# oca_i3c_wrap: IP-XACT component
VLNV tenstorrent.com:ocah:oca_i3c_wrap:1.0

## Address spaces and blocks
oca_i3c_wrap_mmap.oca_i3c_wrap: base 'h0, range 'h6000, width 32

## Registers
Registers are 32-bit, read-write, reset 0x0 unless marked. A register's access mark holds for its fields unless they carry their own. Offsets are from the block's base; lines under a group give offsets from that group; [hi:lo] are bit positions; {n}, {i} and the like mark numbered series; 'fields as' and 'values as' point back to an identical list; <NAME> marks a mode.

## oca_i3c_wrap_mmap.oca_i3c_wrap — Wrapper address map instantiating the per-controller I3C CSR blocks.
Base 0x00000000
{0x0+0x1000*i} i3c_csr[{i}] (i=0..5) group
  0x00 I3CBase group
    0x00 HCI_VERSION ro reset 0x120 — Identifies the implemented MIPI I3C HCI version.
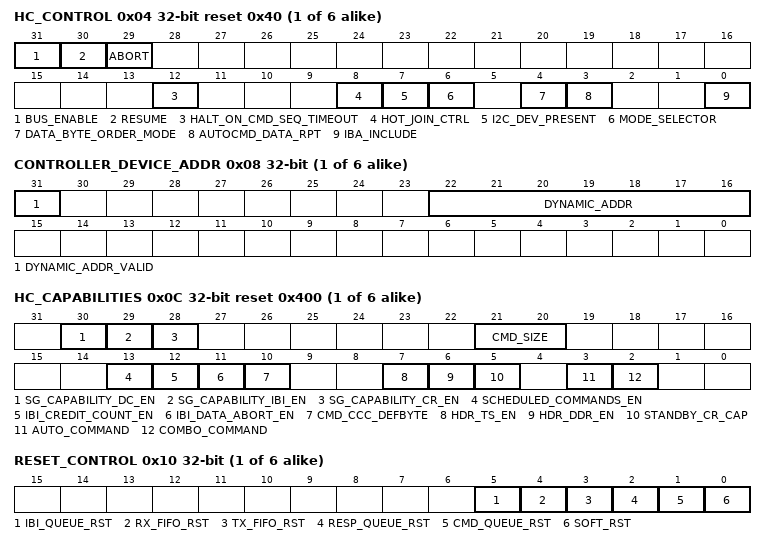
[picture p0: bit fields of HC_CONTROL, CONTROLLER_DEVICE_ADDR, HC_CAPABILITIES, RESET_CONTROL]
    0x04 HC_CONTROL access per field reset 0x40 — Controls host-controller bus operation, mode selection, transaction abort, and Hot-Join handling.
      [31] BUS_ENABLE rw — Host Controller Bus Enable
      [30] RESUME rw write-1-clears — Host Controller Resume: 0 - Controller is running 1 - Controller is suspended Write 1 to resume Controller operations.
      [29] ABORT rw — Host Controller Abort when set to 1
      [12] HALT_ON_CMD_SEQ_TIMEOUT rw — Halt on Command Sequence Timeout when set to 1
      [8] HOT_JOIN_CTRL rw — Hot-Join ACK/NACK Control: 0 - ACK Hot-Join request 1 - NACK Hot-Join request and send Broadcast CCC to disable Hot-Join
      [7] I2C_DEV_PRESENT rw — I2C Device Present on Bus: 0 - pure I3C bus 1 - legacy I2C devices on the bus
      [6] MODE_SELECTOR ro — DMA/PIO Mode Selector: 0 - DMA 1 - PIO
      [4] DATA_BYTE_ORDER_MODE ro — Data Byte Ordering Mode: 0 - Little Endian 1 - Big Endian
      [3] AUTOCMD_DATA_RPT ro — Auto-Command Data Report: 0 - coalesced reporting 1 - separated reporting
      [0] IBA_INCLUDE rw — Include I3C Broadcast Address: 0 - skips I3C Broadcast Address for private transfers 1 - includes I3C Broadcast Address for private transfers
    0x08 CONTROLLER_DEVICE_ADDR — Configures the controller dynamic address and indicates whether that address is valid.
      [31] DYNAMIC_ADDR_VALID — Dynamic Address is Valid: 0 - dynamic address is invalid 1 - dynamic address is valid
      [22:16] DYNAMIC_ADDR — Device Dynamic Address
    0x0C HC_CAPABILITIES ro reset 0x400 — Reports the host-controller capabilities implemented by this instance.
      [30] SG_CAPABILITY_DC_EN — Device context memory: 0 - must be physically continuous 1 - controller supports scatter-gather
      [29] SG_CAPABILITY_IBI_EN — DMA only: IBI status and IBI Data rings memory: 0 - must be physically continuous 1 - controller supports scatter-gather
      [28] SG_CAPABILITY_CR_EN — DMA only: Command and Response rings memory: 0 - must be physically continuous 1 - controller supports scatter-gather
      [21:20] CMD_SIZE — Size and structure of the Command Descriptor: 2'b0: 2 DWORDs, all other reserved.
      [13] SCHEDULED_COMMANDS_EN — Controller command scheduling: 0 - not supported 1 - supported
      [12] IBI_CREDIT_COUNT_EN — Controller IBI credit count: 0 - not supported 1 - supported
      [11] IBI_DATA_ABORT_EN — Controller IBI data abort: 0 - not supported 1 - supported
      [10] CMD_CCC_DEFBYTE — CCC with defining byte: 0 - not supported 1 - supported
      [7] HDR_TS_EN — HDR-Ternary transfers: 0 - not supported 1 - supported
      [6] HDR_DDR_EN — HDR-DDR transfers: 0 - not supported 1 - supported
      [5] STANDBY_CR_CAP — Switching from active to standby mode: 0 - not supported, this controller is always active on I3C 1- supported, this controller can hand off I3C to secondary controller
      [3] AUTO_COMMAND — Automatic read command on IBI: 0 - not supported 1 - supported
      [2] COMBO_COMMAND — Controller combined command: 0 - not supported 1 - supported
    0x10 RESET_CONTROL — Requests a controller soft reset or selective PIO queue and FIFO resets. Reset requests are self-clearing.
      [5] IBI_QUEUE_RST — Clear IBI queue from software. Valid only in PIO mode.
      [4] RX_FIFO_RST — Clear RX FIFO from software. Valid only in PIO mode.
      [3] TX_FIFO_RST — Clear TX FIFO from software. Valid only in PIO mode.
      [2] RESP_QUEUE_RST — Clear response queue from software. Valid only in PIO mode.
      [1] CMD_QUEUE_RST — Clear command queue from software. Valid only in PIO mode.
      [0] SOFT_RST — Reset controller from software. Not supported currently
    0x14 PRESENT_STATE ro — Reports current controller state, including active-controller bus ownership.
      [2] AC_CURRENT_OWN — Controller I3C state: 0 - not bus owner 1 - bus owner
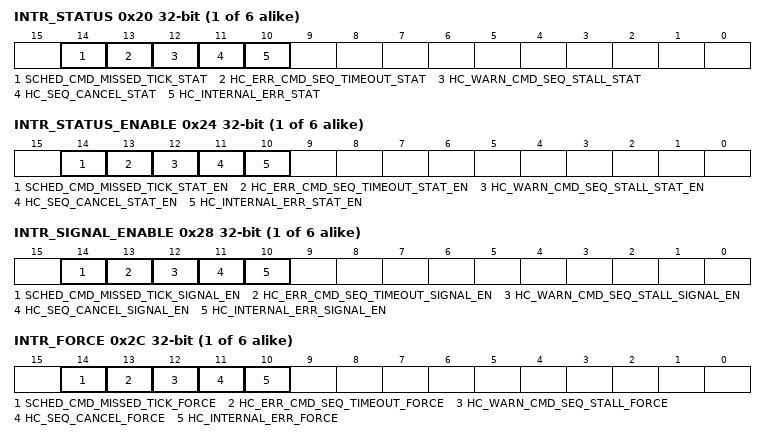
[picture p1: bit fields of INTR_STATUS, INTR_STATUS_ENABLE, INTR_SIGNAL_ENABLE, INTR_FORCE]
    0x20 INTR_STATUS — Reports host-controller error and exceptional-condition status.
      [14] SCHED_CMD_MISSED_TICK_STAT write-1-clears — Scheduled commands could be executed due to controller being busy.
      [13] HC_ERR_CMD_SEQ_TIMEOUT_STAT write-1-clears — Command timeout after prolonged stall.
      [12] HC_WARN_CMD_SEQ_STALL_STAT write-1-clears — Clock stalled due to lack of commands.
      [11] HC_SEQ_CANCEL_STAT write-1-clears — Controller had to cancel command sequence.
      [10] HC_INTERNAL_ERR_STAT write-1-clears — Controller internal unrecoverable error.
    0x24 INTR_STATUS_ENABLE — Enables individual host-controller interrupt status sources.
      [14] SCHED_CMD_MISSED_TICK_STAT_EN — Enable SCHED_CMD_MISSED_TICK_STAT monitoring.
      [13] HC_ERR_CMD_SEQ_TIMEOUT_STAT_EN — Enable HC_ERR_CMD_SEQ_TIMEOUT_STAT monitoring.
      [12] HC_WARN_CMD_SEQ_STALL_STAT_EN — Enable HC_WARN_CMD_SEQ_STALL_STAT monitoring.
      [11] HC_SEQ_CANCEL_STAT_EN — Enable HC_SEQ_CANCEL_STAT monitoring.
      [10] HC_INTERNAL_ERR_STAT_EN — Enable HC_INTERNAL_ERR_STAT monitoring.
    0x28 INTR_SIGNAL_ENABLE — Routes enabled host-controller interrupt sources to the interrupt output.
      [14] SCHED_CMD_MISSED_TICK_SIGNAL_EN — Enable SCHED_CMD_MISSED_TICK_STAT interrupt.
      [13] HC_ERR_CMD_SEQ_TIMEOUT_SIGNAL_EN — Enable HC_ERR_CMD_SEQ_TIMEOUT_STAT interrupt.
      [12] HC_WARN_CMD_SEQ_STALL_SIGNAL_EN — Enable HC_WARN_CMD_SEQ_STALL_STAT interrupt.
      [11] HC_SEQ_CANCEL_SIGNAL_EN — Enable HC_SEQ_CANCEL_STAT interrupt.
      [10] HC_INTERNAL_ERR_SIGNAL_EN — Enable HC_INTERNAL_ERR_STAT interrupt.
    0x2C INTR_FORCE wo — Forces host-controller interrupts for software testing.
      [14] SCHED_CMD_MISSED_TICK_FORCE — Force SCHED_CMD_MISSED_TICK_STAT interrupt.
      [13] HC_ERR_CMD_SEQ_TIMEOUT_FORCE — Force HC_ERR_CMD_SEQ_TIMEOUT_STAT interrupt.
      [12] HC_WARN_CMD_SEQ_STALL_FORCE — Force HC_WARN_CMD_SEQ_STALL_STAT interrupt.
      [11] HC_SEQ_CANCEL_FORCE — Force HC_SEQ_CANCEL_STAT interrupt.
      [10] HC_INTERNAL_ERR_FORCE — Force HC_INTERNAL_ERR_STAT interrupt.
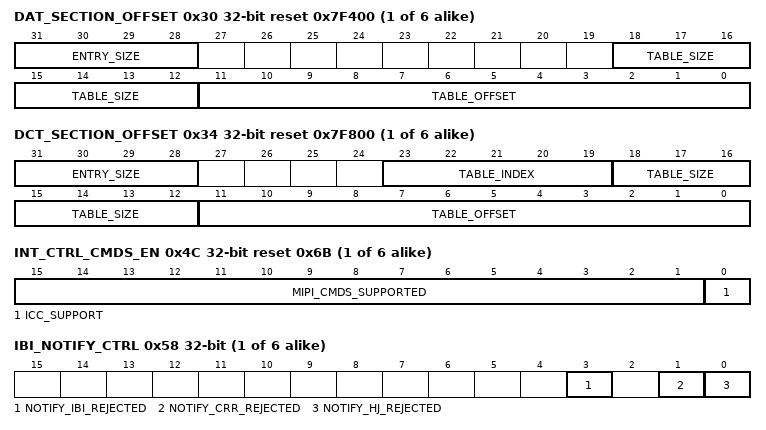
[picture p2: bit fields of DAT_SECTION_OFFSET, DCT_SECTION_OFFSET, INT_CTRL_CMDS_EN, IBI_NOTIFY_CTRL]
    0x30 DAT_SECTION_OFFSET ro reset 0x7F400 — Reports the Device Address Table section offset and size.
      [31:28] ENTRY_SIZE — Individual DAT entry size. 0 - 2 DWRODs, 1:15 - reserved.
      [18:12] TABLE_SIZE — Max number of DAT entries.
      [11:0] TABLE_OFFSET — DAT entry offset in respect to BASE address.
    0x34 DCT_SECTION_OFFSET access per field reset 0x7F800 — Configures the Device Characteristic Table section offset, size, and ENTDAA index.
      [31:28] ENTRY_SIZE ro — Individual DCT entry size. 0 - 4 DWORDs, 1:15 - Reserved.
      [23:19] TABLE_INDEX rw — Index to DCT used during ENTDAA.
      [18:12] TABLE_SIZE ro — Max number of DCT entries.
      [11:0] TABLE_OFFSET ro — DCT entry offset in respect to BASE address.
    0x38 RING_HEADERS_SECTION_OFFSET ro — Ring section offset
      [15:0] SECTION_OFFSET — DMA ring headers section offset. Invalid if 0.
    0x3C PIO_SECTION_OFFSET ro reset 0x80 — Reports the PIO section offset.
      [15:0] SECTION_OFFSET — PIO section offset. Invalid if 0.
    0x40 EXT_CAPS_SECTION_OFFSET ro reset 0x100 — Extended capabilities section offset
      [15:0] SECTION_OFFSET — Extended Capabilities section offset. Invalid if 0.
    0x4C INT_CTRL_CMDS_EN ro reset 0x6B — MIPI commands
      [15:1] MIPI_CMDS_SUPPORTED — Bitmask of supported MIPI commands.
      [0] ICC_SUPPORT — Internal Control Commands: 1 - some or all internals commands sub-commands are supported, 0 - illegal.
    0x58 IBI_NOTIFY_CTRL — I3C interrupts notification
      [3] NOTIFY_IBI_REJECTED — Notify about rejected IBI: 0 - do not enqueue rejected IBI, 1 = enqueue rejected IBI on IBI queue/ring.
      [1] NOTIFY_CRR_REJECTED — Notify about rejected controller role request: 0 - do not enqueue rejected CRR, 1 = enqueue rejected CRR on IBI queue/ring.
      [0] NOTIFY_HJ_REJECTED — Notify about rejected hot-join: 0 - do not enqueue rejected HJ, 1 = enqueue rejected HJ on IBI queue/ring.
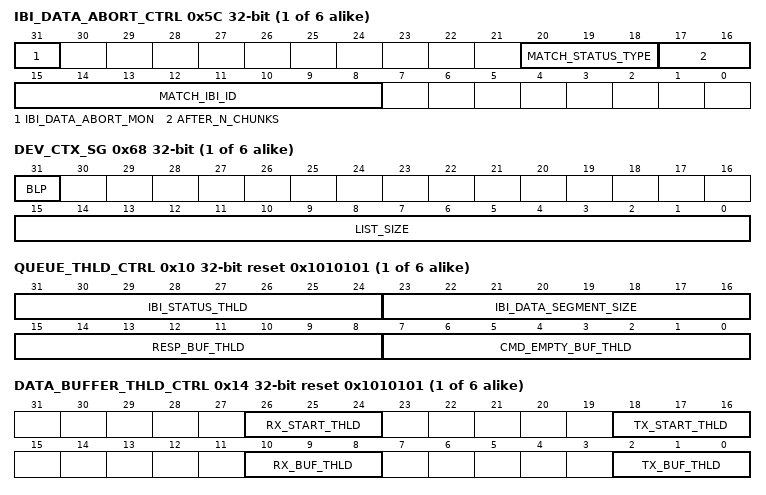
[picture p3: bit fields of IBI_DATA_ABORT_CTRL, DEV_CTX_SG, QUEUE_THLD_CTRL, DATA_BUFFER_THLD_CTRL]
    0x5C IBI_DATA_ABORT_CTRL — IBI data control
      [31] IBI_DATA_ABORT_MON — Enable/disable IBI monitoring logic.
      [20:18] MATCH_STATUS_TYPE — Define which IBI should be aborted: 3'b000 - Regular IBI, 3'b100 - Autocmd IBI, other values - not supported.
      [17:16] AFTER_N_CHUNKS — Number of data chunks to be allowed before forced termination: 0 - immediate, 1:3 - delay by 1-3 data chunks.
      [15:8] MATCH_IBI_ID — IBI target address: [15:9] - device address, [8] - must always be set to 1'b1
    0x60 DEV_CTX_BASE_LO — Device context memory address lower 32 bits
      [0] BASE_LO
    0x64 DEV_CTX_BASE_HI — Device context memory address higher 32 bits
      [0] BASE_HI
    0x68 DEV_CTX_SG ro — SG control
      [31] BLP — Buffer vs list pointer in device context: 0 - continuous physical memory region, 1 - pointer to SG descriptor list.
      [15:0] LIST_SIZE — Number of SG entries.
  0x80 PIOControl group
    0x00 COMMAND_PORT wo reset not defined — Accepts a 64-bit command descriptor as two consecutive 32-bit writes. The second write enqueues the descriptor.
      [31:0] COMMAND_DATA — COMMAND_QUEUE_PORT
    0x04 RESPONSE_PORT ro reset not defined — Returns one 32-bit response descriptor from the response queue.
      [31:0] RESPONSE_DATA — RESPONSE_QUEUE_PORT
    0x08 TX_DATA_PORT wo reset not defined — Writes transmit data to the TX FIFO. This port shares its address with the read-only RX data port.
      [31:0] TX_DATA
    0x08 RX_DATA_PORT ro reset not defined — Reads received data from the RX FIFO. This port shares its address with the write-only TX data port.
      [31:0] RX_DATA
    0x0C IBI_PORT ro reset not defined — Returns IBI status and payload data. Payload data is padded to a 4-byte boundary.
      [31:0] IBI_DATA — Data Read from IBI Data Buffer. The IBI Port is mapped to the IBI Data Queue. IBI Data is always aligned to a 4-byte boundary and then put into the IBI Queue. If the incoming data is not aligned to a 4-byte boundary, then there will be extra (unused) bytes at the end of the transferred IBI data. This can be determined from the value of field DATA_LENGTH in the IBI Status Descriptor.
    0x10 QUEUE_THLD_CTRL reset 0x1010101 — Configures command, response, and IBI queue thresholds as raw entry counts.
      [31:24] IBI_STATUS_THLD — Triggers IBI_STATUS_THLD_STAT interrupt when IBI queue has N or more entries. Accepted values are 1:255
      [23:16] IBI_DATA_SEGMENT_SIZE — IBI Queue data segment size. Valida values are 1:63
      [15:8] RESP_BUF_THLD — Triggers RESP_READY_STAT interrupt when RESP queue has N or more entries. Accepted values are 1:255
      [7:0] CMD_EMPTY_BUF_THLD — Triggers CMD_QUEUE_READY_STAT interrupt when CMD queue has N or more free entries. Accepted values are 1:255
    0x14 DATA_BUFFER_THLD_CTRL reset 0x1010101 — Configures TX and RX start and ready thresholds, each encoding 2^(N+1) entries.
      [26:24] RX_START_THLD — Postpone read command until RX queue has 2^(N+1) free entries
      [18:16] TX_START_THLD — Postpone write command until TX queue has 2^(N+1) entries
      [10:8] RX_BUF_THLD — Trigger RX_THLD_STAT interrupt when RX queue has 2^(N+1) or more entries
      [2:0] TX_BUF_THLD — Trigger TX_THLD_STAT interrupt when TX queue has 2^(N+1) or more free entries
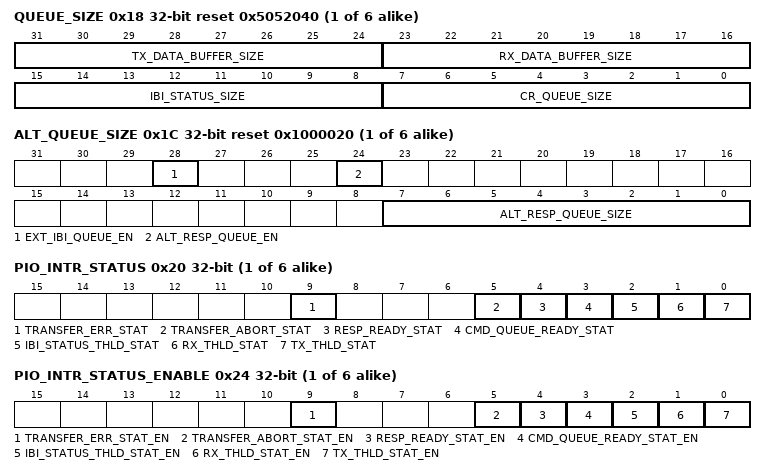
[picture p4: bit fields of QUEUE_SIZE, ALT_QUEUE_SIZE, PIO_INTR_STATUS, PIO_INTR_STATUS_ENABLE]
    0x18 QUEUE_SIZE ro reset 0x5052040 — Reports command, response, IBI, TX, and RX queue depths.
      [31:24] TX_DATA_BUFFER_SIZE — TX queue size is equal to 2^(N+1), where N is this field value
      [23:16] RX_DATA_BUFFER_SIZE — RX queue size is equal to 2^(N+1), where N is this field value
      [15:8] IBI_STATUS_SIZE — IBI Queue size is equal to N
      [7:0] CR_QUEUE_SIZE — Command/Response queue size is equal to N
    0x1C ALT_QUEUE_SIZE ro reset 0x1000020 — Reports extended IBI and alternate response queue sizes.
      [28] EXT_IBI_QUEUE_EN — 1 indicates that IBI queue size is equal to 8*IBI_STATUS_SIZE
      [24] ALT_RESP_QUEUE_EN — If set, response and command queues are not equal lengths, then ALT_RESP_QUEUE_SIZE contains response queue size
      [7:0] ALT_RESP_QUEUE_SIZE — Valid only if ALT_RESP_QUEUE_EN is set. Contains response queue size
    0x20 PIO_INTR_STATUS access per field — Reports PIO queue-threshold and transfer-event interrupt status.
      [9] TRANSFER_ERR_STAT rw write-1-clears — Transfer error
      [5] TRANSFER_ABORT_STAT rw write-1-clears — Transfer aborted
      [4] RESP_READY_STAT ro — Response queue fulfils RESP_BUF_THLD
      [3] CMD_QUEUE_READY_STAT ro — Command queue fulfils CMD_EMPTY_BUF_THLD
      [2] IBI_STATUS_THLD_STAT ro — IBI queue fulfils IBI_STATUS_THLD
      [1] RX_THLD_STAT ro — RX queue fulfils RX_BUF_THLD
      [0] TX_THLD_STAT ro — TX queue fulfils TX_BUF_THLD
    0x24 PIO_INTR_STATUS_ENABLE — Enables individual PIO interrupt status sources.
      [9] TRANSFER_ERR_STAT_EN — Enable transfer error monitoring
      [5] TRANSFER_ABORT_STAT_EN — Enable transfer abort monitoring
      [4] RESP_READY_STAT_EN — Enable response queue monitoring
      [3] CMD_QUEUE_READY_STAT_EN — Enable command queue monitoring
      [2] IBI_STATUS_THLD_STAT_EN — Enable IBI queue monitoring
      [1] RX_THLD_STAT_EN — Enable RX queue monitoring
      [0] TX_THLD_STAT_EN — Enable TX queue monitoring
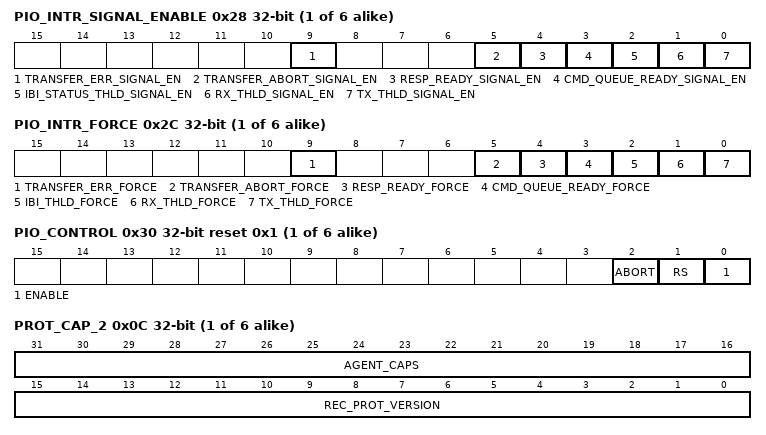
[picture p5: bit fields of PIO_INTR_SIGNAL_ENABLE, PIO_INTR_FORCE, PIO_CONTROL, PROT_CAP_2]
    0x28 PIO_INTR_SIGNAL_ENABLE — Routes enabled PIO interrupt sources to the interrupt output.
      [9] TRANSFER_ERR_SIGNAL_EN — Enable transfer error interrupt
      [5] TRANSFER_ABORT_SIGNAL_EN — Enable transfer abort interrupt
      [4] RESP_READY_SIGNAL_EN — Enable response ready interrupt
      [3] CMD_QUEUE_READY_SIGNAL_EN — Enable command queue interrupt
      [2] IBI_STATUS_THLD_SIGNAL_EN — Enable IBI queue interrupt
      [1] RX_THLD_SIGNAL_EN — Enable RX queue interrupt
      [0] TX_THLD_SIGNAL_EN — Enable TX queue interrupt
    0x2C PIO_INTR_FORCE wo — PIO force interrupt status
      [9] TRANSFER_ERR_FORCE — Force transfer error
      [5] TRANSFER_ABORT_FORCE — Force transfer aborted
      [4] RESP_READY_FORCE — Force response queue interrupt
      [3] CMD_QUEUE_READY_FORCE — Force command queue interrupt
      [2] IBI_THLD_FORCE — Force IBI queue interrupt
      [1] RX_THLD_FORCE — Force RX queue interrupt
      [0] TX_THLD_FORCE — Force TX queue interrupt
    0x30 PIO_CONTROL reset 0x1 — Controls run/stop and forced abort of enqueued commands.
      [2] ABORT — Stop current command descriptor execution forcefully and hold remaining commands. 1 - Request PIO Abort, 0 - Resume PIO execution
      [1] RS — Run/Stop execution of enqueued commands. When set to 0, it holds execution of enqueued commands and runs current command to completion. 1 - PIO Queue start request, 0 - PIO Queue stop request.
      [0] ENABLE — Enables PIO queues. When disabled, SW may not read from/write to PIO queues. 1 - PIO queue enable request, 0 - PIO queue disable request
  0x100 I3C_EC group
    0x00 SecFwRecoveryIf group
      0x00 EXTCAP_HEADER ro reset 0x20C0
        [23:8] CAP_LENGTH — Capability Structure Length in DWORDs
        [7:0] CAP_ID — Extended Capability ID
      0x04 PROT_CAP_0 ro reset 0x2050434F — Recovery Protocol Capabilities 0
        [31:0] REC_MAGIC_STRING_0 — Magic string 'OCP ' (1st part of 'OCP RECV') in ASCII code - '0x4f 0x43 0x50 0x20'
      0x08 PROT_CAP_1 ro reset 0x56434552 — Recovery Protocol Capabilities 1
        [31:0] REC_MAGIC_STRING_1 — Magic string 'RECV' (2nd part of 'OCP RECV') in ASCII code - '0x52 0x45 0x43 0x56'
      0x0C PROT_CAP_2 — Recovery Protocol Capabilities 2
        [31:16] AGENT_CAPS — Agent capabilities: * bit 0: Identification (DEVICE_ID structure) * bit 1: Forced Recovery (From RESET) * bit 2: Mgmt reset (From RESET) * bit 3: Device Reset (From RESET) * bit 4: Device status (DEVICE_STATUS) * bit 5: Recovery memory access (INDIRECT_CTRL) * bit 6: Local C-image support * bit 7: Push C-image support * bit 8: Interface isolation * bit 9: Hardware status * bit 10: Vendor command * bit 11: Flashless boot (From RESET) * bit 12: FIFO CMS support (INDIRECT_FIFO_CTRL) * bits 13-15: Reserved
        [15:0] REC_PROT_VERSION — * Byte 0: Major version number = 0x1 * Byte 1: Minor version number = 0x1
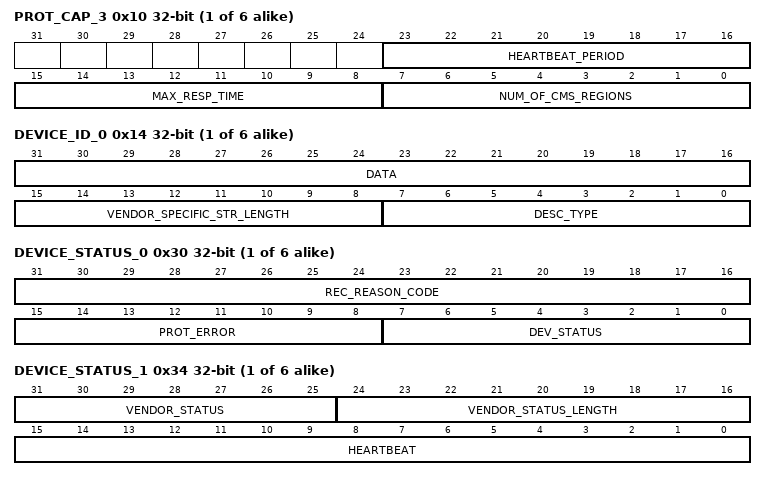
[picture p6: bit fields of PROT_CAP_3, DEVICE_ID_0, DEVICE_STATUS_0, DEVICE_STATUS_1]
      0x10 PROT_CAP_3 — Recovery Protocol Capabilities 3
        [23:16] HEARTBEAT_PERIOD — 0-255: Heartbeat period, 2^x microseconds (us), 0 indicates not supported
        [15:8] MAX_RESP_TIME — 0-255: Maximum response time in 2^x microseconds(us).
        [7:0] NUM_OF_CMS_REGIONS — 0-255: The total number of component memory space (CMS) regions a device supports. This number includes any logging, code and vendor defined regions
      0x14 DEVICE_ID_0 — Device Identification 0
        [31:16] DATA
        [15:8] VENDOR_SPECIFIC_STR_LENGTH — 0x0-0xFF: Total length of Vendor Specific String, 0 indicates not supported
        [7:0] DESC_TYPE — Based on table 8 from [DMTF PLDM FM]: * 0x00: PCI Vendor * 0x1: IANA * 0x2: UUID * 0x3: PnP Vendor * 0x4: ACPI Vendor * 0x5: IANA Enterprise Type * 0x6-0xFE: Reserved * 0xFF: NVMe-MI
      {0x14+4l} DEVICE_ID_{l} (l=1..5) — Device Identification {l}
        [31:0] DATA
      0x2C DEVICE_ID_RESERVED ro — Reserved
        [31:0] DATA
      0x30 DEVICE_STATUS_0
        [31:16] REC_REASON_CODE — * 0x0: No Boot Failure detected (BFNF) * 0x1: Generic hardware error (BFGHWE) * 0x2: Generic hardware soft error (BFGSE) - soft error may be recoverable * 0x3: Self-test failure (BFSTF) (e.g., RSA self test failure, FIPs self test failure,, etc.) * 0x4: Corrupted/missing critical data (BFCD) * 0x5: Missing/corrupt key manifest (BFKMMC) * 0x6: Authentication Failure on key manifest (BFKMAF) * 0x7: Anti-rollback failure on key manifest (BFKIAR) * 0x8: Missing/corrupt boot loader (first mutable code) firmware image (BFFIMC) * 0x9: Authentication failure on boot loader ( 1st mutable code) firmware image (BFFIAF) * 0xA: Anti-rollback failure boot loader (1st mutable code) firmware image (BFFIAR) * 0xB: Missing/corrupt main/management firmware image (BFMFMC) * 0xC: Authentication Failure main/management firmware image (BFMFAF) * 0xD: Anti-rollback Failure main/management firmware image (BFMFAR) * 0xE: Missing/corrupt recovery firmware (BFRFMC) * 0xF: Authentication Failure recovery firmware (BFRFAF) * 0x10: Anti-rollback Failure on recovery firmware (BFRFAR) * 0x11: Forced Recovery (FR) * 0x12: Flashless/Streaming Boot (FSB) * 0x13-0x7F: Reserved * 0x80-0xFF: Vendor Unique Boot Failure Codes
        [15:8] PROT_ERROR read-clears — * 0x0: No Protocol Error * 0x1: Unsupported/Write Command - command is not support or a write to a RO command * 0x2: Unsupported Parameter * 0x3: Length write error (length of write command is incorrect) * 0x4: CRC Error (if supported) * 0x5-0xFE: Reserved * 0xFF: General Protocol Error - catch all unclassified errors
        [7:0] DEV_STATUS — * 0x0: Status Pending (Recover Reason Code not populated) * 0x1: Device healthy (Recover Reason Code not populated) * 0x2: Device Error (“soft” error or other error state) - (Recover Reason Code not populated) * 0x3: Recovery mode - ready to accept recovery image - (Recover Reason Code populated) * 0x4: Recovery Pending (waiting for activation) - (Recover Reason Code populated) * 0x5: Running Recovery Image ( Recover Reason Code not populated) * 0x6-0xD: Reserved * 0xE: Boot Failure (Recover Reason Code populated) * 0xF: Fatal Error (Recover Reason Code not populated) * 0x10-FF:Reserved
      0x34 DEVICE_STATUS_1
        [31:25] VENDOR_STATUS — Vendor defined status message
        [24:16] VENDOR_STATUS_LENGTH — 0-248: Length in bytes of just VENDOR_STATUS. Zero indicates no vendor status and zero additional bytes.
        [15:0] HEARTBEAT — 0-4095: Incrementing number (counter wraps)
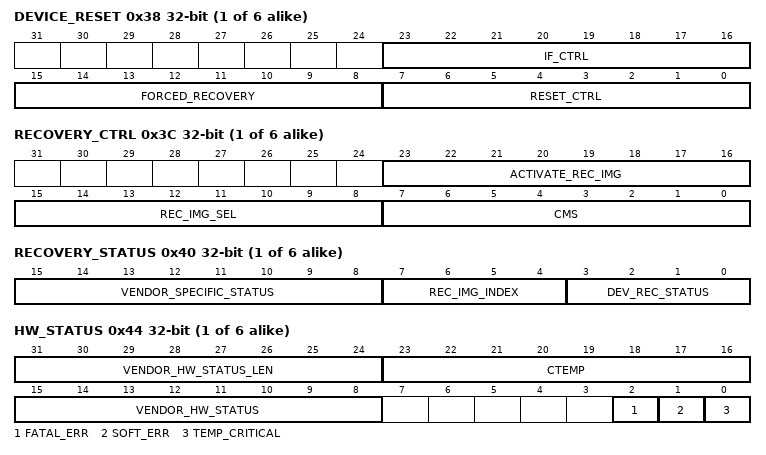
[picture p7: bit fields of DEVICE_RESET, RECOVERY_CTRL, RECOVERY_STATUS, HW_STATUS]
      0x38 DEVICE_RESET — For devices which support reset, this register will reset the device or management entity
        [23:16] IF_CTRL — * 0x0: Disable Interface mastering * 0x1: Enable Interface mastering
        [15:8] FORCED_RECOVERY — * 0x0: No forced recovery * 0x01-0xD: Reserved * 0xE: Enter flashless boot mode on next platform reset * 0xF: Enter recovery mode on next platform reset * 0x10-FF: Reserved
        [7:0] RESET_CTRL write-1-clears — * 0x0: No reset * 0x1: Reset Device (PCIe Fundamental Reset or equivalent. This is likely bus disruptive) * 0x2: Reset Management. This reset will reset the management subsystem. If supported, this reset MUST not be bus disruptive (cause re-enumeration) * 0x3-FF: Reserved
      0x3C RECOVERY_CTRL — Recovery configuration/control
        [23:16] ACTIVATE_REC_IMG write-1-clears — * 0x0: do not activate recovery image - after activation device will report this code. * 0xF: Activate recovery image * 0x10-FF-reserved
        [15:8] REC_IMG_SEL — * 0x0: No operation * 0x1: Use Recovery Image from memory window (CMS) * 0x2: Use Recovery Image stored on device (C-image) * 0x3-FF: reserved
        [7:0] CMS — * 0-255: Selects a component memory space where the recovery image is. 0 is the default
      0x40 RECOVERY_STATUS
        [15:8] VENDOR_SPECIFIC_STATUS
        [7:4] REC_IMG_INDEX — Recovery image index
        [3:0] DEV_REC_STATUS — * 0x0: Not in recovery mode * 0x1: Awaiting recovery image * 0x2: Booting recovery image * 0x3: Recovery successful * 0xc: Recovery failed * 0xd: Recovery image authentication error * 0xe: Error entering Recovery mode (might be administratively disabled) * 0xf: Invalid component address space
      0x44 HW_STATUS — Hardware status
        [31:24] VENDOR_HW_STATUS_LEN — 0-251: Length in bytes of Vendor Specific Hardware Status.
        [23:16] CTEMP — Current temperatureof device in degrees Celsius: Compatible with NVMe-MI command code 0 offset 3. * 0x00-0x7e: 0 to 126 C * 0x7f: 127 C or higher * 0x80: no temperature data, or data is older than 5 seconds * 0x81: temperature sensor failure * 0x82-0x83: reserved * 0xc4: -60 C or lower * 0xc5-0xff: -59 to -1 C (in two's complement)
        [15:8] VENDOR_HW_STATUS — Vendor HW Status (bit mask active high)
        [2] FATAL_ERR — Hardware Fatal Error
        [1] SOFT_ERR — Hardware Soft Error (may need reset to clear)
        [0] TEMP_CRITICAL — Device temperature is critical (may need reset to clear)
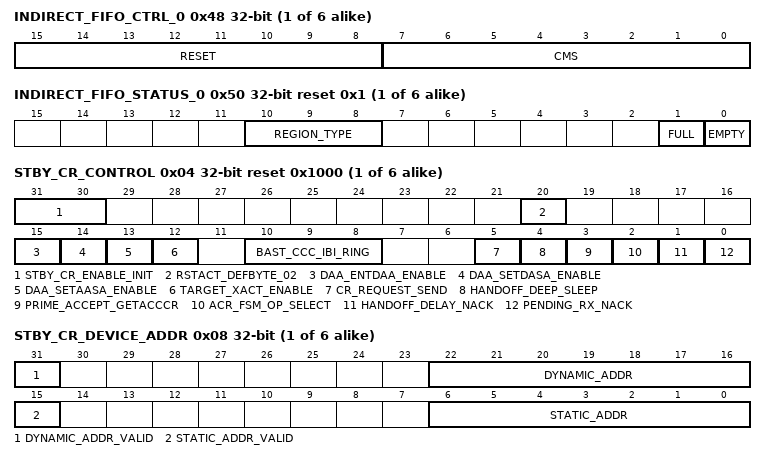
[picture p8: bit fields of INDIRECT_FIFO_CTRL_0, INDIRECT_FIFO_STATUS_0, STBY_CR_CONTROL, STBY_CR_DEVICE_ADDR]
      0x48 INDIRECT_FIFO_CTRL_0 — Indirect FIFO Control 0
        [15:8] RESET — Reset (Write 1 Clear): * 0x0: idle * 0x1: reset Write Index and Read Index to initial value. * 0x2 to 0xFF: reserved
        [7:0] CMS — This register selects a region within the device. Read/write access is through address spaces. Each space represents a FIFO. Component Memory Space (CMS): * 0-255: Address region within a device.
      0x4C INDIRECT_FIFO_CTRL_1 — Indirect FIFO Control 1
        [31:0] IMAGE_SIZE — Image Size: Size of the image to be loaded in 4B units
      0x50 INDIRECT_FIFO_STATUS_0 ro reset 0x1
        [10:8] REGION_TYPE — Memory Region Type: * 0b000: Code space for recovery. (write only) * 0b001: Log uses the defined debug format (read only) * 0b100: Vendor Defined Region (write only) * 0b101: Vendor Defined Region (read only) * 0b111: Unsupported Region (address space out of range)
        [1] FULL — If set, FIFO is full
        [0] EMPTY — If set, FIFO is empty
      0x54 INDIRECT_FIFO_STATUS_1 ro
        [31:0] WRITE_INDEX — Offset incremented for each access by the Recovery Agent in 4B units
      0x58 INDIRECT_FIFO_STATUS_2 ro
        [31:0] READ_INDEX — Offset incremented for each access by the device in 4B units
      0x5C INDIRECT_FIFO_STATUS_3 ro reset 0x40
        [31:0] FIFO_SIZE — Size of memory window specified in 4B units. Current implementation supports only a constant size of 64.
      0x60 INDIRECT_FIFO_STATUS_4 ro reset 0x40
        [31:0] MAX_TRANSFER_SIZE — Max size of the data payload in each read/write to INDIRECT_FIFO_DATA in 4B units Enforced to 256 bytes (64 DWORDs) by Caliptra Subsystem Recovery Sequence
      0x64 INDIRECT_FIFO_RESERVED ro
        [31:0] DATA — Reserved register
      0x68 INDIRECT_FIFO_DATA ro — Indirect memory access to address space configured in INDIRECT_FIFO_CTRL at the Head Pointer offset.
    0x80 StdbyCtrlMode group
      0x00 EXTCAP_HEADER ro reset 0x2012
        fields as i3c_csr[0].I3C_EC.SecFwRecoveryIf.EXTCAP_HEADER
      0x04 STBY_CR_CONTROL access per field reset 0x1000 — Configures standby-controller operation, dynamic-address-assignment methods, target transactions, and controller-role handoff.
        [31:30] STBY_CR_ENABLE_INIT rw — Enables or disables the Secondary Controller: 2'b00 - DISABLED: Secondary Controller is disabled. 2'b01 - ACM_INIT: Secondary Controller is enabled, but Host Controller initializes in Active Controller mode. 2'b10 - SCM_RUNNING: Secondary Controller operation is enabled, Host Controller initializes in Standby Controller mode. 2'b11 - SCM_HOT_JOIN: Secondary Controller operation is enabled, Host Controller conditionally becomes a Hot-Joining Device to receive its Dynamic Address before operating in Standby Controller mode.
        [20] RSTACT_DEFBYTE_02 rw — Controls whether I3C Secondary Controller Logic supports RSTACT CCC with Defining Byte 0x02. 1'b0: NOT_SUPPORTED: Do not ACK Defining Byte 0x02 1'b1: HANDLE_INTR: Support Defining Byte 0x02
        [15] DAA_ENTDAA_ENABLE rw — Indicates ENTDAA method is enabled. 1'b0: DISABLED: will not respond 1'b1: ENABLED: will respond
        [14] DAA_SETDASA_ENABLE rw — Indicates SETDASA method is enabled. 1'b0: DISABLED: will not respond 1'b1: ENABLED: will respond
        [13] DAA_SETAASA_ENABLE rw — Indicates SETAASA method is enabled. 1'b0: DISABLED: will not respond 1'b1: ENABLED: will respond
        [12] TARGET_XACT_ENABLE rw — Indicates whether Read-Type/Write-Type transaction servicing is enabled, via an I3C Target Transaction Interface to software (Section 6.17.3). 1'b0: DISABLED: not available 1'b1: ENABLED: available for software
        [10:8] BAST_CCC_IBI_RING rw — Indicates which Ring Bundle will be used to capture Broadcast CCC data sent by the Active Controller. The Ring Bundle must be configured and enabled, and its IBI Ring Pair must also be initialized and ready to receive data.
        [5] CR_REQUEST_SEND wo — Write of 1'b1 to this field shall instruct the Secondary Controller Logic to attempt to send a Controller Role Request to the I3C Bus.
        [4] HANDOFF_DEEP_SLEEP rw write-sets — If this field has a value of 1'b1, then the Secondary Controller Logic shall report a return from Deep Sleep state to the Active Controller. Writing 1'b1 to this bit is sticky. This field shall automatically clear to 1'b0 after accepting the Controller Role and transitioning to Active Controller mode.
        [3] PRIME_ACCEPT_GETACCCR rw — Prime to Accept Controller Role
        [2] ACR_FSM_OP_SELECT rw — Active Controller Select
        [1] HANDOFF_DELAY_NACK rw
        [0] PENDING_RX_NACK rw
      0x08 STBY_CR_DEVICE_ADDR — Configures standby-controller dynamic and static addresses.
        [31] DYNAMIC_ADDR_VALID — Indicates whether or not the value in the DYNAMIC_ADDR field is valid. 1'b0: DYNAMIC_ADDR field is not valid 1'b1: DYNAMIC_ADDR field is valid
        [22:16] DYNAMIC_ADDR — Contains the Host Controller Device’s Dynamic Address.
        [15] STATIC_ADDR_VALID — Indicates whether or not the value in the STATIC_ADDR field is valid. 1'b0: The Static Address field is not valid 1'b1: The Static Address field is valid
        [6:0] STATIC_ADDR — This field contains the Host Controller Device’s Static Address.
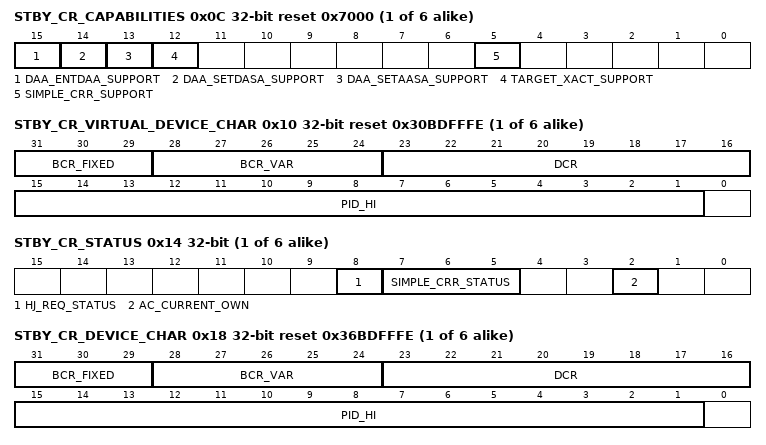
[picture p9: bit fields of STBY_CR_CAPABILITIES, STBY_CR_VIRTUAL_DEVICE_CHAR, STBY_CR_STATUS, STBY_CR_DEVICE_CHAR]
      0x0C STBY_CR_CAPABILITIES ro reset 0x7000 — Reports standby-controller capabilities.
        [15] DAA_ENTDAA_SUPPORT — Defines whether Dynamic Address Assignment with ENTDAA CCC is supported. 1'b0: DISABLED: Not supported 1'b1: ENABLED: Supported
        [14] DAA_SETDASA_SUPPORT — Defines whether Dynamic Address Assignment with SETDASA CCC (using Static Address) is supported. 1'b0: DISABLED: Not supported 1'b1: ENABLED: Supported
        [13] DAA_SETAASA_SUPPORT — Defines whether Dynamic Address Assignment with SETAASA CCC (using Static Address) is supported. 1'b0: DISABLED: Not supported 1'b1: ENABLED: Supported
        [12] TARGET_XACT_SUPPORT — Defines whether an I3C Target Transaction Interface is supported. 1'b0: DISABLED: Not supported 1'b1: ENABLED: Supported via vendor-defined Extended Capability structure
        [5] SIMPLE_CRR_SUPPORT
      0x10 STBY_CR_VIRTUAL_DEVICE_CHAR reset 0x30BDFFFE — Standby Controller Virtual Device Characteristics
        [31:29] BCR_FIXED — Bus Characteristics, Fixed Part. Reset value is set to 3'b001, because this device is an I3C Target, which supports extended capabilities. This field is Read-Only while the STBY_CR_ENABLE_INIT field in register STBY_CR_CONTROL is not zero.
        [28:24] BCR_VAR — Bus Characteristics, Variable Part. Reset value is set to 5'b10000, because this device: - [bit4] is a Virtual Target - [bit3] is not Offline Capable - [bit2] does not apply due to bit1 - [bit1] is not capable of IBI requests - [bit0] has no speed limitation This field is Read-Only while the STBY_CR_ENABLE_INIT field in register STBY_CR_CONTROL is not zero.
        [23:16] DCR — Device Characteristics Register. Value represents an OCP Recovery Device. This field is Read-Only while the STBY_CR_ENABLE_INIT field in register STBY_CR_CONTROL is not zero.
        [15:1] PID_HI — High part of the 48-bit Target Device Provisioned ID. This field is Read-Only while the STBY_CR_ENABLE_INIT field in register STBY_CR_CONTROL is not zero.
      0x14 STBY_CR_STATUS — Standby Controller Status
        [8] HJ_REQ_STATUS, [7:5] SIMPLE_CRR_STATUS, [2] AC_CURRENT_OWN
      0x18 STBY_CR_DEVICE_CHAR reset 0x36BDFFFE — Standby Controller Device Characteristics
        [31:29] BCR_FIXED — Bus Characteristics, Fixed Part. Reset value is set to 3'b001, because this device is an I3C Target, which supports extended capabilities This field is Read-Only while the STBY_CR_ENABLE_INIT field in register STBY_CR_CONTROL is not zero.
        [28:24] BCR_VAR — Bus Characteristics, Variable Part. Reset value is set to 5'b10110, because this device: - [bit4] exposes a Virtual Target - [bit3] is not Offline Capable - [bit2] (always) uses the MDB in the IBI Payload - [bit1] is capable of IBI requests - [bit0] has no speed limitation This field is Read-Only while the STBY_CR_ENABLE_INIT field in register STBY_CR_CONTROL is not zero.
        [23:16] DCR — Device Characteristics Register. Value represents an OCP Recovery Device. This field is Read-Only while the STBY_CR_ENABLE_INIT field in register STBY_CR_CONTROL is not zero.
        [15:1] PID_HI — High part of the 48-bit Target Device Provisioned ID. This field is Read-Only while the STBY_CR_ENABLE_INIT field in register STBY_CR_CONTROL is not zero.
      0x1C STBY_CR_DEVICE_PID_LO reset 0x5A00A5 — Standby Controller Device PID Low
        [31:0] PID_LO — Low part of the 48-bit Target Device Provisioned ID. This field is Read-Only while the STBY_CR_ENABLE_INIT field in register STBY_CR_CONTROL is not zero.
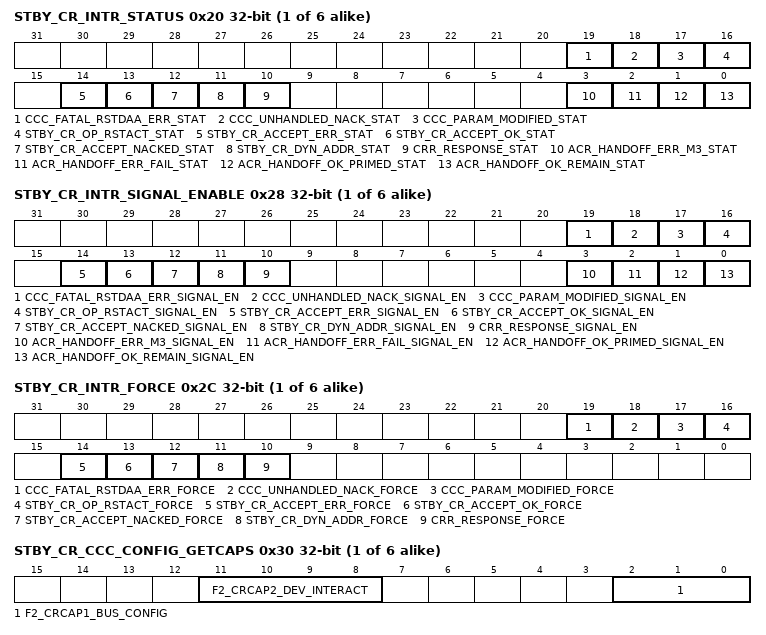
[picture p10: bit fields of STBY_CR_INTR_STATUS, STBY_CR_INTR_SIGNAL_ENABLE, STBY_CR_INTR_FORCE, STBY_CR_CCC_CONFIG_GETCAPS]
      0x20 STBY_CR_INTR_STATUS — Standby Controller Interrupt Status
        [19] CCC_FATAL_RSTDAA_ERR_STAT
        [18] CCC_UNHANDLED_NACK_STAT
        [17] CCC_PARAM_MODIFIED_STAT
        [16] STBY_CR_OP_RSTACT_STAT — The Host Controller shall write 1'b1 to this field to indicate that the Secondary Controller received a RSTACT CCC from the Active Controller, followed by the Target Reset Pattern.
        [14] STBY_CR_ACCEPT_ERR_STAT
        [13] STBY_CR_ACCEPT_OK_STAT
        [12] STBY_CR_ACCEPT_NACKED_STAT
        [11] STBY_CR_DYN_ADDR_STAT
        [10] CRR_RESPONSE_STAT
        [3] ACR_HANDOFF_ERR_M3_STAT
        [2] ACR_HANDOFF_ERR_FAIL_STAT
        [1] ACR_HANDOFF_OK_PRIMED_STAT
        [0] ACR_HANDOFF_OK_REMAIN_STAT
      0x24 STBY_CR_VIRTUAL_DEVICE_PID_LO reset 0x5A10A5 — Standby Controller Virtual Device PID Low
        [31:0] PID_LO — Low part of the 48-bit Target Virtual Device Provisioned ID. This field is Read-Only while the STBY_CR_ENABLE_INIT field in register STBY_CR_CONTROL is not zero.
      0x28 STBY_CR_INTR_SIGNAL_ENABLE — When set to 1'b1, and the corresponding interrupt status field is set in register STBY_CR_INTR_STATUS, the Host Controller shall assert an interrupt to the Host.
        [19] CCC_FATAL_RSTDAA_ERR_SIGNAL_EN, [18] CCC_UNHANDLED_NACK_SIGNAL_EN, [17] CCC_PARAM_MODIFIED_SIGNAL_EN, [16] STBY_CR_OP_RSTACT_SIGNAL_EN, [14] STBY_CR_ACCEPT_ERR_SIGNAL_EN, [13] STBY_CR_ACCEPT_OK_SIGNAL_EN, [12] STBY_CR_ACCEPT_NACKED_SIGNAL_EN, [11] STBY_CR_DYN_ADDR_SIGNAL_EN, [10] CRR_RESPONSE_SIGNAL_EN, [3] ACR_HANDOFF_ERR_M3_SIGNAL_EN, [2] ACR_HANDOFF_ERR_FAIL_SIGNAL_EN, [1] ACR_HANDOFF_OK_PRIMED_SIGNAL_EN, [0] ACR_HANDOFF_OK_REMAIN_SIGNAL_EN
      0x2C STBY_CR_INTR_FORCE access per field — For software testing, when set to 1'b1, forces the corresponding interrupt to be sent to the Host, if the corresponding fields are set in register STBY_CR_INTR_SIGNAL_ENABLE
        [19] CCC_FATAL_RSTDAA_ERR_FORCE rw, [18] CCC_UNHANDLED_NACK_FORCE rw, [17] CCC_PARAM_MODIFIED_FORCE rw, [16] STBY_CR_OP_RSTACT_FORCE wo, [14] STBY_CR_ACCEPT_ERR_FORCE rw, [13] STBY_CR_ACCEPT_OK_FORCE rw, [12] STBY_CR_ACCEPT_NACKED_FORCE rw, [11] STBY_CR_DYN_ADDR_FORCE rw, [10] CRR_RESPONSE_FORCE rw
      0x30 STBY_CR_CCC_CONFIG_GETCAPS — Standby Controller CCC Configuration GETCAPS
        [11:8] F2_CRCAP2_DEV_INTERACT, [2:0] F2_CRCAP1_BUS_CONFIG
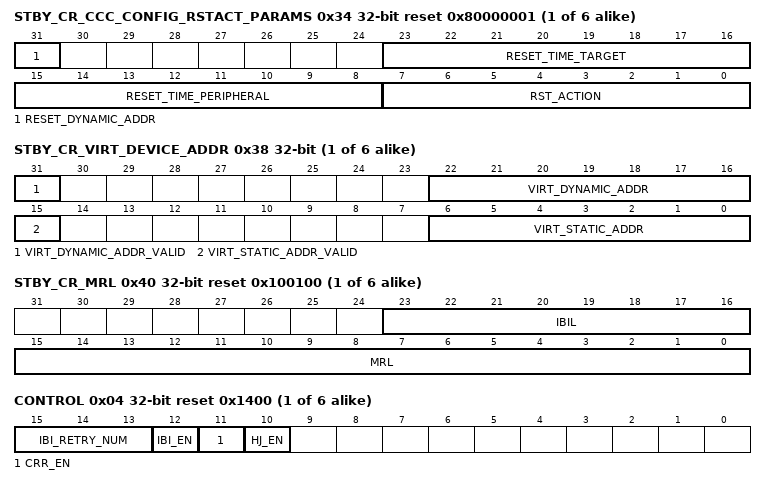
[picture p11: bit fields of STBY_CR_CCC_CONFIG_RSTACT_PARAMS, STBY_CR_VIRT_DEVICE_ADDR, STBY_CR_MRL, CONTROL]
      0x34 STBY_CR_CCC_CONFIG_RSTACT_PARAMS access per field reset 0x80000001 — Reports the defining byte of the last RSTACT CCC received and configures the reset recovery times.
        [31] RESET_DYNAMIC_ADDR rw — If set to 1'b1, then the Secondary Controller Logic must clear its Dynamic Address in register STBY_CR_DEVICE_ADDR after receiving a Target Reset Pattern that followed a Broadcast or Direct SET RSTACT CCC sent to the Dynamic Address, with Defining Byte 0x01 or 0x02. Requires support for Dynamic Address Assignment with at least one supported method, such as the ENTDAA CCC, with field DAA_ENTDAA_ENABLE set to 1'b1 in register STBY_CR_CONTROL. If field ACR_FSM_OP_SELECT in register STBY_CR_CONTROL is set to 1'b1, then this field shall be cleared (i.e., readiness to accept the Controller Role shall be revoked) with this Target Reset Pattern.
        [23:16] RESET_TIME_TARGET rw — For Direct GET CCC, this field is returned for Defining Byte 0x82.
        [15:8] RESET_TIME_PERIPHERAL rw — For Direct GET CCC, this field is returned for Defining Byte 0x81.
        [7:0] RST_ACTION ro — Contains the Defining Byte received with the last Direct SET CCC sent by the Active Controller. If not armed (START or RSTACT with unsupported defining byte) set to spec default 0x1.
      0x38 STBY_CR_VIRT_DEVICE_ADDR — Standby Virtual Controller Device Address
        [31] VIRT_DYNAMIC_ADDR_VALID — Indicates whether or not the value in the VIRT_DYNAMIC_ADDR field is valid. 1'b0: VIRT_DYNAMIC_ADDR field is not valid 1'b1: VIRT_DYNAMIC_ADDR field is valid
        [22:16] VIRT_DYNAMIC_ADDR — Contains the Controller Virtual Device’s Dynamic Address.
        [15] VIRT_STATIC_ADDR_VALID — Indicates whether or not the value in the VIRT_STATIC_ADDR field is valid. 1'b0: The Virtual Device Static Address field is not valid 1'b1: The Virtual Device Static Address field is valid
        [6:0] VIRT_STATIC_ADDR — This field contains the Host Controller Device’s Static Address.
      0x3C STBY_CR_MWL ro reset 0x100 — Standby Controller Maximum Write Length (read-only)
        [15:0] MWL — This field contains the maximum write length (MWL) (read-only)
      0x40 STBY_CR_MRL ro reset 0x100100 — Standby Controller Maximum Read Length and IBI Payload Size (read-only)
        [23:16] IBIL — This field contains the IBI payload size (IBIL) (read-only)
        [15:0] MRL — This field contains the maximum read length (MRL) (read-only)
    0x100 TTI group
      0x00 EXTCAP_HEADER ro reset 0x40C4
        fields as i3c_csr[0].I3C_EC.SecFwRecoveryIf.EXTCAP_HEADER
      0x04 CONTROL reset 0x1400
        [15:13] IBI_RETRY_NUM — Number of times the Target Device will try to request an IBI before giving up. Values: 0x0 - Device will never retry. 0x1-0x6 - Device will retry this many times. 0x7 - Device will retry indefinitely until the Active Controller sets DISINT bit in the DISEC command.
        [12] IBI_EN — Enable the IBI queue servicing. Values: 0x0 - Device will not service the IBI queue. 0x1 - Device will send IBI requests onto the bus, if possible.
        [11] CRR_EN — Enable Controller Role Request. Values: 0x0 - Device is allowed to perform Controller Role Request. 0x1 - Device is not allowed to perform Controller Role Request.
        [10] HJ_EN — Enable Hot-Join capability. Values: 0x0 - Device is allowed to attempt Hot-Join. 0x1 - Device is not allowed to attempt Hot-Join.
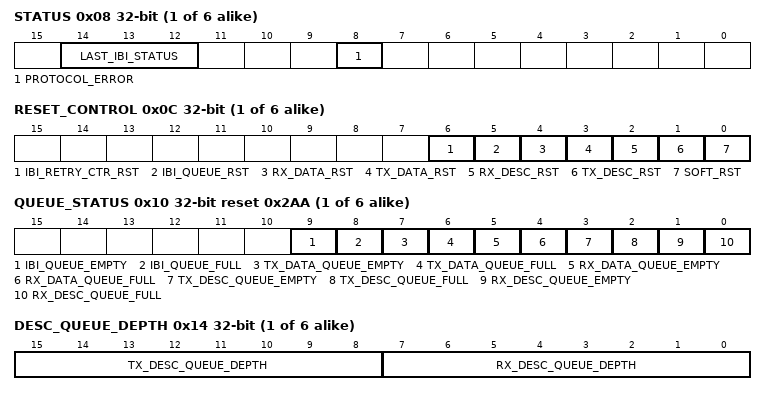
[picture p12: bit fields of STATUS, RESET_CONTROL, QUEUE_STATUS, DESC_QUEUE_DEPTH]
      0x08 STATUS ro
        [14:12] LAST_IBI_STATUS — Status of last IBI. Should be read after IBI_DONE interrupt. Values: 000 - Success: IBI was transmitted and ACK'd by the Active Controller. 001 - FailureNack: Active Controller NACK'd the IBI before any data was sent. The device will retry sending the IBI as long as permitted by the retry counter. 010 - FailurePartialData: Active Controller NACK'd the IBI after data was partially sent. The remaining part of data in the IBI queue is considered corrupted and will be discarded. 011 - FailureRetry: IBI could not be serviced due to reached retry count. 100 - FailureArbitration:: IBI could not be serviced as arbitration was lost during the address header. The device will retry sending the IBI as long as permitted by the retry counter.
        [8] PROTOCOL_ERROR — Protocol error occurred in the past. This field can only be reset by the Controller, if it issues the GETSTATUS CCC. Values: 0 - no error occurred 1 - generic protocol error occurred in the past. It will be set until reception of the next GETSTATUS command.
      0x0C RESET_CONTROL access per field — Reset Control for Queues and IBI Retry Counter
        [6] IBI_RETRY_CTR_RST wo — TTI IBI Retry Counter Software Reset
        [5] IBI_QUEUE_RST rw — TTI IBI Queue Buffer Software Reset
        [4] RX_DATA_RST rw — TTI RX Data Queue Buffer Software Reset
        [3] TX_DATA_RST rw — TTI TX Data Queue Buffer Software Reset. Also resets the tti_conv_Nto8 since first dword is immediately loaded into the converter and can't be cleared otherwise.
        [2] RX_DESC_RST rw — TTI RX Descriptor Queue Buffer Software Reset
        [1] TX_DESC_RST rw — TTI TX Descriptor Queue Buffer Software Reset
        [0] SOFT_RST rw — Target Core Software Reset
      0x10 QUEUE_STATUS ro reset 0x2AA — Dynamic queue full/empty status for debug and monitoring
        [9] IBI_QUEUE_EMPTY — IBI Queue is empty
        [8] IBI_QUEUE_FULL — IBI Queue is full
        [7] TX_DATA_QUEUE_EMPTY — TX Data Queue is empty
        [6] TX_DATA_QUEUE_FULL — TX Data Queue is full
        [5] RX_DATA_QUEUE_EMPTY — RX Data Queue is empty
        [4] RX_DATA_QUEUE_FULL — RX Data Queue is full
        [3] TX_DESC_QUEUE_EMPTY — TX Descriptor Queue is empty
        [2] TX_DESC_QUEUE_FULL — TX Descriptor Queue is full
        [1] RX_DESC_QUEUE_EMPTY — RX Descriptor Queue is empty
        [0] RX_DESC_QUEUE_FULL — RX Descriptor Queue is full
      0x14 DESC_QUEUE_DEPTH ro — Current number of entries in descriptor queues
        [15:8] TX_DESC_QUEUE_DEPTH — Number of entries in TX Descriptor Queue
        [7:0] RX_DESC_QUEUE_DEPTH — Number of entries in RX Descriptor Queue
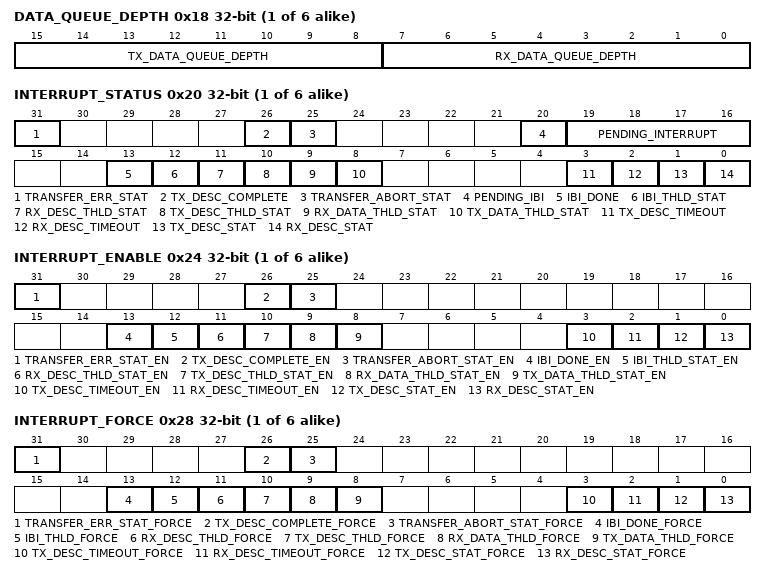
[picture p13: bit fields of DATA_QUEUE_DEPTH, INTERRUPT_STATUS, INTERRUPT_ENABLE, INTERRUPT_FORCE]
      0x18 DATA_QUEUE_DEPTH ro — Current number of DWORD entries in data queues
        [15:8] TX_DATA_QUEUE_DEPTH — Number of DWORD entries in TX Data Queue
        [7:0] RX_DATA_QUEUE_DEPTH — Number of DWORD entries in RX Data Queue
      0x1C IBI_QUEUE_DEPTH ro — Current number of entries in IBI queue
        [7:0] IBI_QUEUE_DEPTH — Number of entries in IBI Queue
      0x20 INTERRUPT_STATUS access per field — Interrupt Status. How a bit is cleared depends on the bit: - Auto-cleared by hardware on a specific access: RX_DESC_STAT, RX_DESC_THLD_STAT and RX_DATA_THLD_STAT clear when software reads the corresponding RX queue; IBI_DONE clears when software reads STATUS.LAST_IBI_STATUS. These bits are also write-1-to-clear, but the normal servicing access clears them without an explicit write here. - Write-1-to-clear only (no hardware auto-clear): TX_DESC_COMPLETE, TX_DESC_STAT, TX_DESC_THLD_STAT, TX_DATA_THLD_STAT, IBI_THLD_STAT, and the not-implemented TRANSFER_ERR_STAT, TRANSFER_ABORT_STAT, TX_DESC_TIMEOUT, RX_DESC_TIMEOUT. Write 1 to the bit in this register to clear it. - Read-only, hardware-driven level status that cannot be cleared by software: PENDING_IBI and PENDING_INTERRUPT track live conditions.
        [31] TRANSFER_ERR_STAT rw write-1-clears — NOT IMPLEMENTED. Bus error occurred. Clear: write 1 to this bit in INTERRUPT_STATUS (no hardware auto-clear).
        [26] TX_DESC_COMPLETE rw write-1-clears — Read Transaction on the I3C Bus completed. Clear: write 1 to this bit in INTERRUPT_STATUS (no hardware auto-clear).
        [25] TRANSFER_ABORT_STAT rw write-1-clears — NOT IMPLEMENTED. Bus aborted transaction. Clear: write 1 to this bit in INTERRUPT_STATUS (no hardware auto-clear).
        [20] PENDING_IBI ro — At least one IBI is pending. Read-only, hardware-driven level status: it tracks the live IBI-pending condition and cannot be cleared by software (clears automatically when no IBI is pending).
        [19:16] PENDING_INTERRUPT rw — Contains the interrupt number of any pending interrupt, or 0 if no interrupts are pending. This encoding allows for up to 15 numbered interrupts. If more than one interrupt is set, then the highest priority interrupt shall be returned. Read-only, hardware-driven level status: it cannot be cleared by software and updates as pending conditions change.
        [13] IBI_DONE rw write-1-clears — IBI is done, check LAST_IBI_STATUS for result. Clear: auto-cleared by hardware when software reads STATUS.LAST_IBI_STATUS; writing 1 to this bit in INTERRUPT_STATUS also clears it.
        [12] IBI_THLD_STAT rw write-1-clears — TTI IBI Buffer Threshold Status, the Target Controller shall set this bit to 1 when the number of available entries in the TTI IBI Queue is >= the value defined in `TTI_IBI_THLD`. Clear: write 1 to this bit in INTERRUPT_STATUS (no hardware auto-clear).
        [11] RX_DESC_THLD_STAT rw write-1-clears — TTI RX Descriptor Buffer Threshold Status, the Target Controller shall set this bit to 1 when the number of available entries in the TTI RX Descriptor Queue is >= the value defined in `TTI_RX_DESC_THLD`. Clear: auto-cleared by hardware when software reads the RX Descriptor Queue; writing 1 to this bit in INTERRUPT_STATUS also clears it.
        [10] TX_DESC_THLD_STAT rw write-1-clears — TTI TX Descriptor Buffer Threshold Status, the Target Controller shall set this bit to 1 when the number of available entries in the TTI TX Descriptor Queue is >= the value defined in `TTI_TX_DESC_THLD`. Clear: write 1 to this bit in INTERRUPT_STATUS (no hardware auto-clear).
        [9] RX_DATA_THLD_STAT rw write-1-clears — TTI RX Data Buffer Threshold Status, the Target Controller shall set this bit to 1 when the number of entries in the TTI RX Data Queue is >= the value defined in `TTI_RX_DATA_THLD`. Clear: auto-cleared by hardware when software reads the RX Data Queue; writing 1 to this bit in INTERRUPT_STATUS also clears it.
        [8] TX_DATA_THLD_STAT rw write-1-clears — TTI TX Data Buffer Threshold Status, the Target Controller shall set this bit to 1 when the number of available entries in the TTI TX Data Queue is >= the value defined in `TTI_TX_DATA_THLD`. Clear: write 1 to this bit in INTERRUPT_STATUS (no hardware auto-clear).
        [3] TX_DESC_TIMEOUT rw write-1-clears — NOT IMPLEMENTED. Pending Read was NACK’ed, because the `TX_DESC_STAT` event was not handled in time. Clear: write 1 to this bit in INTERRUPT_STATUS (no hardware auto-clear).
        [2] RX_DESC_TIMEOUT rw write-1-clears — NOT IMPLEMENTED. Pending Write was NACK’ed, because the `RX_DESC_STAT` event was not handled in time. Clear: write 1 to this bit in INTERRUPT_STATUS (no hardware auto-clear).
        [1] TX_DESC_STAT rw write-1-clears — There is a pending Read Transaction on the I3C Bus. Software should write data to the TX Descriptor Queue and the TX Data Queue. Clear: write 1 to this bit in INTERRUPT_STATUS (no hardware auto-clear — writing to the TX queues does not clear it).
        [0] RX_DESC_STAT rw write-1-clears — There is a pending Write Transaction. Software should read data from the RX Descriptor Queue and the RX Data Queue. Clear: auto-cleared by hardware when software reads the RX Descriptor Queue; writing 1 to this bit in INTERRUPT_STATUS also clears it.
      0x24 INTERRUPT_ENABLE
        [31] TRANSFER_ERR_STAT_EN — Enables the corresponding interrupt bit `TRANSFER_ERR_STAT`
        [26] TX_DESC_COMPLETE_EN — Enables the corresponding interrupt bit `TX_DESC_COMPLETE_EN`
        [25] TRANSFER_ABORT_STAT_EN — Enables the corresponding interrupt bit `TRANSFER_ABORT_STAT`
        [13] IBI_DONE_EN — Enables the corresponding interrupt bit `IBI_DONE`
        [12] IBI_THLD_STAT_EN — Enables the corresponding interrupt bit `TTI_IBI_THLD_STAT`
        [11] RX_DESC_THLD_STAT_EN — Enables the corresponding interrupt bit `TTI_RX_DESC_THLD_STAT`
        [10] TX_DESC_THLD_STAT_EN — Enables the corresponding interrupt bit `TTI_TX_DESC_THLD_STAT`
        [9] RX_DATA_THLD_STAT_EN — Enables the corresponding interrupt bit `TTI_RX_DATA_THLD_STAT`
        [8] TX_DATA_THLD_STAT_EN — Enables the corresponding interrupt bit `TTI_TX_DATA_THLD_STAT`
        [3] TX_DESC_TIMEOUT_EN — Enables the corresponding interrupt bit `TX_DESC_TIMEOUT_EN`
        [2] RX_DESC_TIMEOUT_EN — Enables the corresponding interrupt bit `RX_DESC_TIMEOUT_EN`
        [1] TX_DESC_STAT_EN — Enables the corresponding interrupt bit `TX_DESC_STAT_EN`
        [0] RX_DESC_STAT_EN — Enables the corresponding interrupt bit `RX_DESC_STAT_EN`
      0x28 INTERRUPT_FORCE
        [31] TRANSFER_ERR_STAT_FORCE — Enables the corresponding interrupt bit `TRANSFER_ERR_STAT_FORCE`
        [26] TX_DESC_COMPLETE_FORCE — Enables the corresponding interrupt bit `TX_DESC_COMPLETE_FORCE`
        [25] TRANSFER_ABORT_STAT_FORCE — Enables the corresponding interrupt bit `TRANSFER_ABORT_STAT_FORCE`
        [13] IBI_DONE_FORCE — Enables the corresponding interrupt bit `IBI_DONE_FORCE`
        [12] IBI_THLD_FORCE — Forces the corresponding interrupt bit `TTI_IBI_THLD_STAT` to be set to 1
        [11] RX_DESC_THLD_FORCE — Forces the corresponding interrupt bit `TTI_RX_DESC_THLD_STAT` to be set to `1`
        [10] TX_DESC_THLD_FORCE — Forces the corresponding interrupt bit `TTI_TX_DESC_THLD_STAT` to be set to `1`
        [9] RX_DATA_THLD_FORCE — Forces the corresponding interrupt bit `TTI_RX_DATA_THLD_STAT` to be set to `1`
        [8] TX_DATA_THLD_FORCE — Forces the corresponding interrupt bit `TTI_TX_DATA_THLD_STAT` to be set to `1`
        [3] TX_DESC_TIMEOUT_FORCE — Enables the corresponding interrupt bit `TX_DESC_TIMEOUT_FORCE`
        [2] RX_DESC_TIMEOUT_FORCE — Enables the corresponding interrupt bit `RX_DESC_TIMEOUT_FORCE`
        [1] TX_DESC_STAT_FORCE — Enables the corresponding interrupt bit `TX_DESC_STAT_FORCE`
        [0] RX_DESC_STAT_FORCE — Enables the corresponding interrupt bit `RX_DESC_STAT_FORCE`
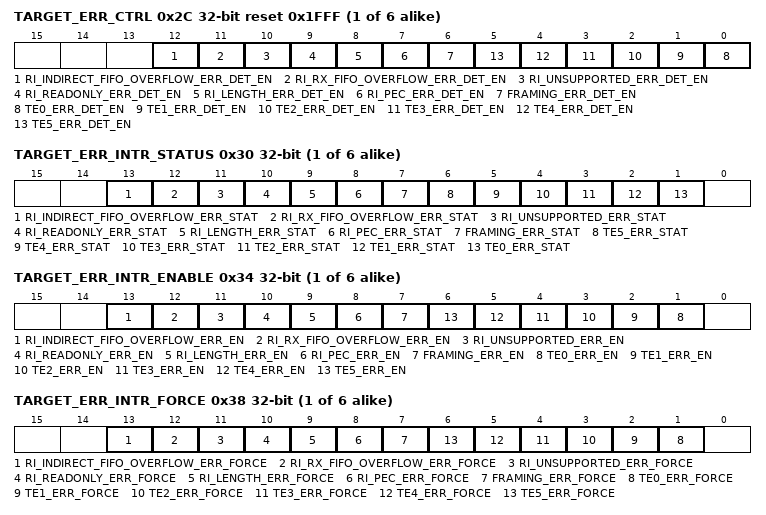
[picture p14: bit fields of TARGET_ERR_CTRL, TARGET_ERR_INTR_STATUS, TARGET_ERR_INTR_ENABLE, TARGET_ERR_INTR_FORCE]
      0x2C TARGET_ERR_CTRL reset 0x1FFF — Target Error Detection Control. Set bits to enable error detection. Clear to disable.
        [12] RI_INDIRECT_FIFO_OVERFLOW_ERR_DET_EN — Enable Recovery Interface INDIRECT FIFO overflow error detection and transition to Error state. Set to 0 to disable (overflow is still recorded in interrupt status).
        [11] RI_RX_FIFO_OVERFLOW_ERR_DET_EN — Enable Recovery Interface RX FIFO overflow error detection and transition to Error state. Set to 0 to disable (overflow is still recorded in interrupt status).
        [10] RI_UNSUPPORTED_ERR_DET_EN — Enable Recovery Interface unsupported command error detection. Set to 0 to disable.
        [9] RI_READONLY_ERR_DET_EN — Enable Recovery Interface write-to-read-only error detection. Set to 0 to disable.
        [8] RI_LENGTH_ERR_DET_EN — Enable Recovery Interface length error detection. Set to 0 to disable.
        [7] RI_PEC_ERR_DET_EN — Enable Recovery Interface PEC/CRC error detection. Set to 0 to disable.
        [6] FRAMING_ERR_DET_EN — Enable framing error detection. Set to 0 to disable.
        [n] TE{n}_ERR_DET_EN (n=0..5) — Enable TE{n} error detection. Set to 0 to disable.
      0x30 TARGET_ERR_INTR_STATUS — Target Error Interrupt Status. Write 1 to clear individual bits.
        [13] RI_INDIRECT_FIFO_OVERFLOW_ERR_STAT write-1-clears — Recovery Interface INDIRECT FIFO overflow error detected
        [12] RI_RX_FIFO_OVERFLOW_ERR_STAT write-1-clears — Recovery Interface RX FIFO overflow error detected
        [11] RI_UNSUPPORTED_ERR_STAT write-1-clears — Recovery Interface unsupported command error detected
        [10] RI_READONLY_ERR_STAT write-1-clears — Recovery Interface write-to-read-only error detected
        [9] RI_LENGTH_ERR_STAT write-1-clears — Recovery Interface length mismatch error detected
        [8] RI_PEC_ERR_STAT write-1-clears — Recovery Interface PEC/CRC error detected
        [7] FRAMING_ERR_STAT write-1-clears — DA padding error (Bit[0] != 0 in SETDASA/SETNEWDA)
        [6] TE5_ERR_STAT write-1-clears — TE5: Broadcast/Direct CCC wrong R/W direction
        [5] TE4_ERR_STAT write-1-clears — TE4: ENTDAA BCR/DCR mismatch
        [4] TE3_ERR_STAT write-1-clears — TE3: ENTDAA PID mismatch
        [3] TE2_ERR_STAT write-1-clears — TE2: CCC or Private Write data parity error
        [2] TE1_ERR_STAT write-1-clears — TE1: CCC command parity error
        [1] TE0_ERR_STAT write-1-clears — TE0: Invalid reserved address + RnW combination
      0x34 TARGET_ERR_INTR_ENABLE — Target Error Interrupt Enable. Set bits to enable corresponding interrupts.
        [13] RI_INDIRECT_FIFO_OVERFLOW_ERR_EN — Enables the corresponding interrupt bit `RI_INDIRECT_FIFO_OVERFLOW_ERR_STAT`
        [12] RI_RX_FIFO_OVERFLOW_ERR_EN — Enables the corresponding interrupt bit `RI_RX_FIFO_OVERFLOW_ERR_STAT`
        [11] RI_UNSUPPORTED_ERR_EN — Enables the corresponding interrupt bit `RI_UNSUPPORTED_ERR_STAT`
        [10] RI_READONLY_ERR_EN — Enables the corresponding interrupt bit `RI_READONLY_ERR_STAT`
        [9] RI_LENGTH_ERR_EN — Enables the corresponding interrupt bit `RI_LENGTH_ERR_STAT`
        [8] RI_PEC_ERR_EN — Enables the corresponding interrupt bit `RI_PEC_ERR_STAT`
        [7] FRAMING_ERR_EN — Enables the corresponding interrupt bit `FRAMING_ERR_STAT`
        [n+1] TE{n}_ERR_EN (n=0..5) — Enables the corresponding interrupt bit `TE{n}_ERR_STAT`
      0x38 TARGET_ERR_INTR_FORCE — Target Error Interrupt Force. Set bits to force corresponding interrupts for testing.
        [13] RI_INDIRECT_FIFO_OVERFLOW_ERR_FORCE — Forces the corresponding interrupt bit `RI_INDIRECT_FIFO_OVERFLOW_ERR_STAT` to be set to 1
        [12] RI_RX_FIFO_OVERFLOW_ERR_FORCE — Forces the corresponding interrupt bit `RI_RX_FIFO_OVERFLOW_ERR_STAT` to be set to 1
        [11] RI_UNSUPPORTED_ERR_FORCE — Forces the corresponding interrupt bit `RI_UNSUPPORTED_ERR_STAT` to be set to 1
        [10] RI_READONLY_ERR_FORCE — Forces the corresponding interrupt bit `RI_READONLY_ERR_STAT` to be set to 1
        [9] RI_LENGTH_ERR_FORCE — Forces the corresponding interrupt bit `RI_LENGTH_ERR_STAT` to be set to 1
        [8] RI_PEC_ERR_FORCE — Forces the corresponding interrupt bit `RI_PEC_ERR_STAT` to be set to 1
        [7] FRAMING_ERR_FORCE — Forces the corresponding interrupt bit `FRAMING_ERR_STAT` to be set to 1
        [n+1] TE{n}_ERR_FORCE (n=0..5) — Forces the corresponding interrupt bit `TE{n}_ERR_STAT` to be set to 1
      {0x3C+4l} TARGET_ERR_CNT_TE{l} (l=0..5) — Counts TE{l} errors. Saturates at 255. Write 0 to clear.
        [7:0] CNT — Error count (saturates at 255). Write 0 to clear.
      0x54 TARGET_ERR_CNT_FRAMING — Counts framing errors. Saturates at 255. Write 0 to clear.
        [7:0] CNT — Error count (saturates at 255). Write 0 to clear.
      0x58 TARGET_ERR_CNT_RI_PEC — Counts Recovery Interface PEC errors. Saturates at 255. Write 0 to clear.
        [7:0] CNT — Error count (saturates at 255). Write 0 to clear.
      0x5C TARGET_ERR_CNT_RI_LENGTH — Counts Recovery Interface length mismatch errors. Saturates at 255. Write 0 to clear.
        [7:0] CNT — Error count (saturates at 255). Write 0 to clear.
      0x60 TARGET_ERR_CNT_RI_READONLY — Counts Recovery Interface write-to-read-only errors. Saturates at 255. Write 0 to clear.
        [7:0] CNT — Error count (saturates at 255). Write 0 to clear.
      0x64 TARGET_ERR_CNT_RI_UNSUPPORTED — Counts Recovery Interface unsupported command errors. Saturates at 255. Write 0 to clear.
        [7:0] CNT — Error count (saturates at 255). Write 0 to clear.
      0x68 TARGET_ERR_CNT_RI_RX_FIFO_OVERFLOW — Counts Recovery Interface RX FIFO overflow errors. Saturates at 255. Write 0 to clear.
        [7:0] CNT — Error count (saturates at 255). Write 0 to clear.
      0x6C TARGET_ERR_CNT_RI_INDIRECT_FIFO_OVERFLOW — Counts Recovery Interface INDIRECT FIFO overflow errors. Saturates at 255. Write 0 to clear.
        [7:0] CNT — Error count (saturates at 255). Write 0 to clear.
      0x70 RX_DESC_QUEUE_PORT ro — RX Descriptor Queue Port
        [31:0] RX_DESC — RX Data
      0x74 RX_DATA_PORT ro
        [31:0] RX_DATA
      0x78 TX_DESC_QUEUE_PORT wo — TX Descriptor Queue Port
        [31:0] TX_DESC — TX Data
      0x7C TX_DATA_PORT wo
        [31:0] TX_DATA
      0x80 IBI_PORT wo — IBI Data Port
        [31:0] IBI_DATA
      0x84 QUEUE_SIZE ro reset 0x5050404
        [31:24] TX_DATA_BUFFER_SIZE — Transmit Data Buffer Size in DWORDs calculated as `2^(N+1)`
        [23:16] RX_DATA_BUFFER_SIZE — Receive Data Buffer Size in DWORDs calculated as `2^(N+1)`
        [15:8] TX_DESC_BUFFER_SIZE — TX Descriptor Buffer Size in DWORDs calculated as `2^(N+1)`
        [7:0] RX_DESC_BUFFER_SIZE — RX Descriptor Buffer Size in DWORDs calculated as `2^(N+1)`
      0x88 IBI_QUEUE_SIZE ro reset 0x4
        [7:0] IBI_QUEUE_SIZE — IBI Queue Size in DWORDs calculated as `2^(N+1)`
      0x8C QUEUE_THLD_CTRL reset 0x1000101 — Queue Threshold Control
        [31:24] IBI_THLD — Controls the minimum number of IBI Queue entries needed to trigger the IBI threshold interrupt.
        [15:8] RX_DESC_THLD — Controls the minimum number of TTI RX Descriptor Queue entries needed to trigger the TTI RX Descriptor interrupt.
        [7:0] TX_DESC_THLD — Controls the minimum number of empty TTI TX Descriptor Queue entries needed to trigger the TTI TX Descriptor interrupt.
      0x90 DATA_BUFFER_THLD_CTRL reset 0x1010101 — IBI Queue Threshold Control
        [26:24] RX_START_THLD — Minimum number of TTI RX Data queue entries of data received, in DWORDs, that will trigger the TTI RX Data interrupt. Interrupt triggers when `2^(N+1)` RX Buffer DWORD entries are received during the Read transfer.
        [18:16] TX_START_THLD — Minimum number of available TTI TX Data queue entries, in DWORDs, that will trigger the TTI TX Data interrupt. Interrupt triggers when `2^(N+1)` TX Buffer DWORD entries are available.
        [10:8] RX_DATA_THLD — Minimum number of TTI RX Data queue entries of data received, in DWORDs, that will trigger the TTI RX Data interrupt. Interrupt triggers when `2^(N+1)` RX Buffer DWORD entries are received during the Read transfer.
        [2:0] TX_DATA_THLD — Minimum number of available TTI TX Data queue entries, in DWORDs, that will trigger the TTI TX Data interrupt. Interrupt triggers when `2^(N+1)` TX Buffer DWORD entries are available.
    0x200 SoCMgmtIf group
      0x00 EXTCAP_HEADER ro reset 0x1AC1
        fields as i3c_csr[0].I3C_EC.SecFwRecoveryIf.EXTCAP_HEADER
      0x04 SOC_MGMT_CONTROL — SoC Management Control
        [31:0] PLACEHOLDER
      0x08 SOC_MGMT_STATUS — SoC Management Status
        [31:0] PLACEHOLDER
      0x0C REC_INTF_CFG — Configures the recovery interface and signals payload completion to the recovery handler.
        [1] REC_PAYLOAD_DONE — Inform Recovery Handler that payload transfer is finished.
        [0] REC_INTF_BYPASS — Choose Recovery Interface access type: * 0 - I3C Core * 1 - direct AXI
      0x10 REC_INTF_REG_W1C_ACCESS — Mock hardware register access
        [23:16] INDIRECT_FIFO_CTRL_RESET — Write to 'Indirect memory configuration - reset' register, mocking a hardware access (bypassing 'write 1 to clear' register property).
        [15:8] RECOVERY_CTRL_ACTIVATE_REC_IMG — Write to 'Recovery Control - Activate Recovery Image' register, mocking a hardware access (bypassing 'write 1 to clear' register property).
        [7:0] DEVICE_RESET_CTRL — Write to 'Reset control - Device Reset Control' register, mocking a hardware access (bypassing 'write 1 to clear' register property).
      0x14 SOC_MGMT_RSVD_2
        [31:0] PLACEHOLDER
      0x18 SOC_MGMT_RSVD_3
        [31:0] PLACEHOLDER
      0x1C SOC_PAD_CONF reset 0x1000001 — I3C Pad Configuration Register
        [31:24] PAD_TYPE — Select pad type 0 - Bidirectional 1 - Open-drain 2 - Input-only 3 - Analog input
        [7] VIRTUAL_OD_EN — Enable virtual open drain: 0 - disabled 1 - enabled
        [6] OD_EN — Enable Open-Drain: 0 - disabled 1 - enabled
        [5] IO_INVERSION — Invert I/O signal: 0 - signals pass-through 1 - signals are inverted
        [4] PULL_EN — Enable Pull: 0 - disabled 1 - enabled
        [3] PULL_DIR — Direction of the pull: 0 - Pull down 1 - Pull up
        [2] KEEPER_EN — Enable the High-Keeper: 0 - disabled 1 - enabled
        [1] SCHMITT_EN — Enable the Schmitt Trigger: 0 - disabled 1 - enabled
        [0] INPUT_ENABLE — Enable input: 0 - enabled 1 - disabled
      0x20 SOC_PAD_ATTR reset 0xF000F00 — I3C Pad Attribute Configuration Register
        [31:24] DRIVE_STRENGTH — Select driver strength '0 - lowest '1 - highest
        [15:8] DRIVE_SLEW_RATE — Select driver slew rate '0 - lowest '1 - highest
      0x24 SOC_MGMT_FEATURE_2
        [31:0] PLACEHOLDER — Reserved for: I/O ring and pad configuration
      0x28 SOC_MGMT_FEATURE_3
        [31:0] PLACEHOLDER — Reserved for: I/O ring and pad configuration
      0x2C T_R_REG
        [19:0] T_R — Rise time of both SDA and SCL in clock units
      0x30 T_F_REG
        [19:0] T_F — Fall time of both SDA and SCL in clock units
      0x34 T_SU_DAT_REG
        [19:0] T_SU_DAT — Data setup time in clock units
      0x38 T_SU_DAT_I2C_REG
        [19:0] T_SU_DAT_I2C — Data setup time in I2C mode in clock units
      0x3C T_HD_DAT_REG
        [19:0] T_HD_DAT — Data hold time in clock units
      0x40 T_HIGH_REG
        [19:0] T_HIGH — High period of the SCL in clock units
      0x44 T_HIGH_OD_REG
        [19:0] T_HIGH_OD — High period of the SCL in Open-Drain mode in clock units
      0x48 T_HIGH_INIT_OD_REG
        [19:0] T_HIGH_INIT_OD — High period of the SCL in Open-Drain mode during bus initialization in clock units
      0x4C T_HIGH_I2C_REG
        [19:0] T_HIGH_I2C — High period of the SCL in I2C mode in clock units
      0x50 T_LOW_REG
        [19:0] T_LOW — Low period of the SCL in clock units
      0x54 T_LOW_OD_REG
        [19:0] T_LOW_OD — Low period of the SCL in Open-Drain mode in clock units
      0x58 T_LOW_I2C_REG
        [19:0] T_LOW_I2C — Low period of the SCL in I2C mode in clock units
      0x5C T_HD_STA_REG
        [19:0] T_HD_STA — Hold time for START in clock units
      0x60 T_HD_STA_I2C_REG
        [19:0] T_HD_STA_I2C — Hold time for START in I2C mode in clock units
      0x64 T_HD_RSTA_REG
        [19:0] T_HD_RSTA — Hold time for repeated START in clock units
      0x68 T_SU_STA_REG
        [19:0] T_SU_STA — Setup time for repeated START in clock units
      0x6C T_SU_STA_I2C_REG
        [19:0] T_SU_STA_I2C — Setup time for repeated START in I2C mode in clock units
      0x70 T_SU_STO_REG
        [19:0] T_SU_STO — Setup time for STOP in clock units
      0x74 T_SU_STO_I2C_REG
        [19:0] T_SU_STO_I2C — Setup time for STOP in in I2C mode clock units
      0x78 T_DS_OD_REG
        [19:0] T_DS_OD — Setup time for SDA during START in clock units
      0x7C T_FREE_REG reset 0xC
        [31:0] T_FREE — Bus Free Time Between a STOP and a START
      0x80 T_FREE_I2C_REG reset 0xC
        [31:0] T_FREE_I2C — Bus Free Time Between a STOP and a START in I2C mode
      0x84 T_AVAL_REG reset 0x12C
        [31:0] T_AVAL
      0x88 T_IDLE_REG reset 0xEA60
        [31:0] T_IDLE — Time in clock cycles from STOP detection until Bus Idle Condition (tIDLE). Configure based on System Clock
      0x8C HDR_TIMEOUT_EN_REG
        [0] HDR_TIMEOUT_EN — Enable bit for the optional 60us HDR error recovery timer (I3C spec 5.1.10.1.9). When enabled, the Target can recover from TE0/TE1 errors if both SCL and SDA stay High for a period exceeding the configured threshold. Disabled on reset.
      0x90 T_HDR_TIMEOUT_REG reset 0xEA60
        [19:0] T_HDR_TIMEOUT — Timer threshold in clock cycles for the optional HDR error recovery (I3C spec 5.1.10.1.9). If both SCL and SDA stay High for this many clock cycles during a TE0/TE1 error-induced HDR mode, the Target exits HDR mode and returns to Idle. Configure based on System Clock to achieve 60us.
    0x298 CtrlCfg group
      0x00 EXTCAP_HEADER ro reset 0x202
        fields as i3c_csr[0].I3C_EC.SecFwRecoveryIf.EXTCAP_HEADER
      0x04 CONTROLLER_CONFIG ro reset 0x10
        [5:4] OPERATION_MODE
    0x2A0 TERMINATION_EXTCAP_HEADER ro reset 0x100 — Register after the last EC must advertise ID == 0. Termination register is added to guarantee that the discovery mechanism reaches termination value.
      fields as i3c_csr[0].I3C_EC.SecFwRecoveryIf.EXTCAP_HEADER

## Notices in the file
SPDX-License-Identifier: Apache-2.0
SPDX-FileCopyrightText: 2026 Tenstorrent USA, Inc.
